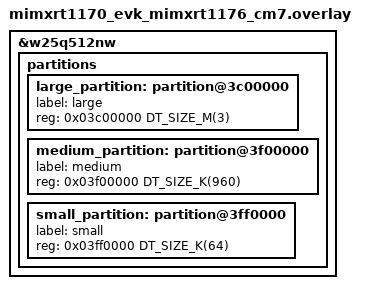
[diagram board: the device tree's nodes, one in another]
/*
 * Copyright 2025 NXP
 *
 * SPDX-License-Identifier: Apache-2.0
 */

/delete-node/ &storage_partition;

&w25q512nw {
	partitions {
		large_partition: partition@3c00000 {
			label = "large";
			reg = <0x03c00000 DT_SIZE_M(3)>;
		};

		medium_partition: partition@3f00000 {
			label = "medium";
			reg = <0x03f00000 DT_SIZE_K(960)>;
		};

		small_partition: partition@3ff0000 {
			label = "small";
			reg = <0x03ff0000 DT_SIZE_K(64)>;
		};
	};
};
